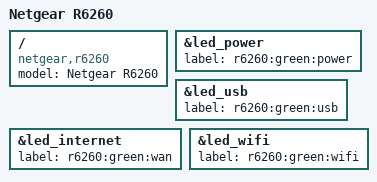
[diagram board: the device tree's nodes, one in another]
// SPDX-License-Identifier: GPL-2.0
/dts-v1/;

#include "mt7621_netgear_sercomm_chj.dtsi"

/ {
	compatible = "netgear,r6260", "mediatek,mt7621-soc";
	model = "Netgear R6260";
};

&led_power {
	label = "r6260:green:power";
};

&led_usb {
	label = "r6260:green:usb";
};

&led_internet {
	label = "r6260:green:wan";
};

&led_wifi {
	label = "r6260:green:wifi";
};
